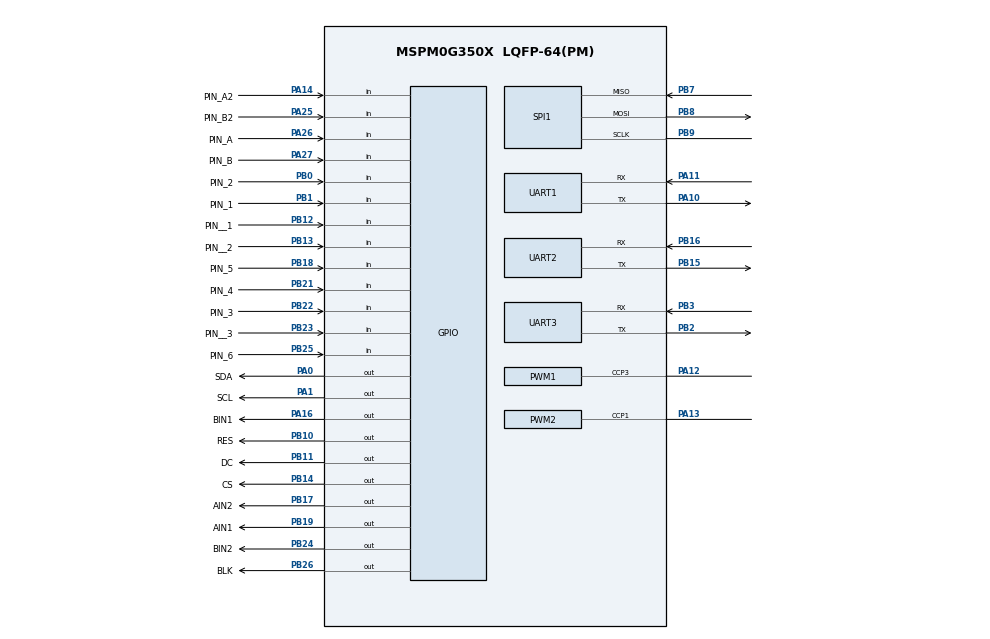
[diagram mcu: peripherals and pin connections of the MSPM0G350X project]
/**
 * @cliArgs --device "MSPM0G350X" --part "Default" --package "LQFP-64(PM)" --product "mspm0_sdk@2.11.00.07"
 * @versions {"tool":"1.26.2+4477"}
 */

/**
 * Import the modules used in this configuration.
 */
const GPIO    = scripting.addModule("/ti/driverlib/GPIO", {}, false);
const GPIO1   = GPIO.addInstance();
const GPIO2   = GPIO.addInstance();
const GPIO3   = GPIO.addInstance();
const GPIO4   = GPIO.addInstance();
const GPIO5   = GPIO.addInstance();
const GPIO6   = GPIO.addInstance();
const NONMAIN = scripting.addModule("/ti/driverlib/NONMAIN");
const PWM     = scripting.addModule("/ti/driverlib/PWM", {}, false);
const PWM1    = PWM.addInstance();
const PWM2    = PWM.addInstance();
const SPI     = scripting.addModule("/ti/driverlib/SPI", {}, false);
const SPI1    = SPI.addInstance();
const SYSCTL  = scripting.addModule("/ti/driverlib/SYSCTL");
const TIMER   = scripting.addModule("/ti/driverlib/TIMER", {}, false);
const TIMER1  = TIMER.addInstance();
const UART    = scripting.addModule("/ti/driverlib/UART", {}, false);
const UART1   = UART.addInstance();
const UART2   = UART.addInstance();
const UART3   = UART.addInstance();
const UART4   = UART.addInstance();

/**
 * Write custom configuration values to the imported modules.
 */
const gate7  = system.clockTree["MFCLKGATE"];
gate7.enable = true;

GPIO1.$name                          = "TB6612";
GPIO1.associatedPins.create(4);
GPIO1.associatedPins[0].$name        = "AIN1";
GPIO1.associatedPins[0].initialValue = "SET";
GPIO1.associatedPins[0].assignedPort = "PORTB";
GPIO1.associatedPins[0].assignedPin  = "19";
GPIO1.associatedPins[0].pin.$assign  = "PB19";
GPIO1.associatedPins[1].$name        = "AIN2";
GPIO1.associatedPins[1].initialValue = "SET";
GPIO1.associatedPins[1].assignedPort = "PORTB";
GPIO1.associatedPins[1].assignedPin  = "17";
GPIO1.associatedPins[1].pin.$assign  = "PB17";
GPIO1.associatedPins[2].$name        = "BIN1";
GPIO1.associatedPins[2].initialValue = "SET";
GPIO1.associatedPins[2].assignedPort = "PORTA";
GPIO1.associatedPins[2].assignedPin  = "16";
GPIO1.associatedPins[2].pin.$assign  = "PA16";
GPIO1.associatedPins[3].$name        = "BIN2";
GPIO1.associatedPins[3].initialValue = "SET";
GPIO1.associatedPins[3].assignedPort = "PORTB";
GPIO1.associatedPins[3].assignedPin  = "24";
GPIO1.associatedPins[3].pin.$assign  = "PB24";

const Board = scripting.addModule("/ti/driverlib/Board", {}, false);

GPIO2.$name                         = "LCD";
GPIO2.port                          = "PORTB";
GPIO2.associatedPins.create(4);
GPIO2.associatedPins[0].$name       = "RES";
GPIO2.associatedPins[0].ioStructure = "SD";
GPIO2.associatedPins[0].assignedPin = "10";
GPIO2.associatedPins[0].pin.$assign = "PB10";
GPIO2.associatedPins[1].$name       = "DC";
GPIO2.associatedPins[1].ioStructure = "SD";
GPIO2.associatedPins[1].assignedPin = "11";
GPIO2.associatedPins[1].pin.$assign = "PB11";
GPIO2.associatedPins[2].$name       = "CS";
GPIO2.associatedPins[2].assignedPin = "14";
GPIO2.associatedPins[2].ioStructure = "SD";
GPIO2.associatedPins[2].pin.$assign = "PB14";
GPIO2.associatedPins[3].$name       = "BLK";
GPIO2.associatedPins[3].ioStructure = "SD";
GPIO2.associatedPins[3].assignedPin = "26";
GPIO2.associatedPins[3].pin.$assign = "PB26";

GPIO3.port                                = "PORTA";
GPIO3.$name                               = "ENCODER";
GPIO3.associatedPins.create(4);
GPIO3.associatedPins[0].direction         = "INPUT";
GPIO3.associatedPins[0].interruptEn       = true;
GPIO3.associatedPins[0].interruptPriority = "0";
GPIO3.associatedPins[0].polarity          = "RISE";
GPIO3.associatedPins[0].$name             = "PIN_A";
GPIO3.associatedPins[0].assignedPin       = "26";
GPIO3.associatedPins[0].pin.$assign       = "PA26";
GPIO3.associatedPins[1].direction         = "INPUT";
GPIO3.associatedPins[1].interruptEn       = true;
GPIO3.associatedPins[1].polarity          = "RISE";
GPIO3.associatedPins[1].$name             = "PIN_B";
GPIO3.associatedPins[1].interruptPriority = "3";
GPIO3.associatedPins[1].assignedPin       = "27";
GPIO3.associatedPins[1].pin.$assign       = "PA27";
GPIO3.associatedPins[2].$name             = "PIN_A2";
GPIO3.associatedPins[2].direction         = "INPUT";
GPIO3.associatedPins[2].interruptEn       = true;
GPIO3.associatedPins[2].interruptPriority = "0";
GPIO3.associatedPins[2].polarity          = "RISE";
GPIO3.associatedPins[2].assignedPin       = "14";
GPIO3.associatedPins[2].pin.$assign       = "PA14";
GPIO3.associatedPins[3].$name             = "PIN_B2";
GPIO3.associatedPins[3].direction         = "INPUT";
GPIO3.associatedPins[3].interruptEn       = true;
GPIO3.associatedPins[3].polarity          = "RISE";
GPIO3.associatedPins[3].assignedPin       = "25";
GPIO3.associatedPins[3].pin.$assign       = "PA25";

GPIO4.$name                              = "TRACKING";
GPIO4.port                               = "PORTB";
GPIO4.associatedPins.create(6);
GPIO4.associatedPins[0].$name            = "PIN_1";
GPIO4.associatedPins[0].direction        = "INPUT";
GPIO4.associatedPins[0].internalResistor = "PULL_UP";
GPIO4.associatedPins[0].assignedPin      = "1";
GPIO4.associatedPins[0].pin.$assign      = "PB1";
GPIO4.associatedPins[1].$name            = "PIN_2";
GPIO4.associatedPins[1].direction        = "INPUT";
GPIO4.associatedPins[1].internalResistor = "PULL_UP";
GPIO4.associatedPins[1].assignedPin      = "0";
GPIO4.associatedPins[1].pin.$assign      = "PB0";
GPIO4.associatedPins[2].$name            = "PIN_3";
GPIO4.associatedPins[2].direction        = "INPUT";
GPIO4.associatedPins[2].internalResistor = "PULL_UP";
GPIO4.associatedPins[2].assignedPin      = "22";
GPIO4.associatedPins[2].pin.$assign      = "PB22";
GPIO4.associatedPins[3].$name            = "PIN_4";
GPIO4.associatedPins[3].direction        = "INPUT";
GPIO4.associatedPins[3].internalResistor = "PULL_UP";
GPIO4.associatedPins[3].assignedPin      = "21";
GPIO4.associatedPins[3].pin.$assign      = "PB21";
GPIO4.associatedPins[4].$name            = "PIN_5";
GPIO4.associatedPins[4].direction        = "INPUT";
GPIO4.associatedPins[4].internalResistor = "PULL_UP";
GPIO4.associatedPins[4].assignedPin      = "18";
GPIO4.associatedPins[4].pin.$assign      = "PB18";
GPIO4.associatedPins[5].$name            = "PIN_6";
GPIO4.associatedPins[5].direction        = "INPUT";
GPIO4.associatedPins[5].internalResistor = "PULL_UP";
GPIO4.associatedPins[5].assignedPin      = "25";
GPIO4.associatedPins[5].pin.$assign      = "PB25";

GPIO5.$name                          = "IIC_Software";
GPIO5.port                           = "PORTA";
GPIO5.associatedPins.create(2);
GPIO5.associatedPins[0].$name        = "SCL";
GPIO5.associatedPins[0].assignedPin  = "1";
GPIO5.associatedPins[0].initialValue = "SET";
GPIO5.associatedPins[0].ioStructure  = "OD";
GPIO5.associatedPins[0].pin.$assign  = "PA1";
GPIO5.associatedPins[1].$name        = "SDA";
GPIO5.associatedPins[1].ioStructure  = "OD";
GPIO5.associatedPins[1].initialValue = "SET";
GPIO5.associatedPins[1].assignedPin  = "0";
GPIO5.associatedPins[1].pin.$assign  = "PA0";

GPIO6.port                               = "PORTB";
GPIO6.$name                              = "KEY";
GPIO6.associatedPins.create(3);
GPIO6.associatedPins[0].direction        = "INPUT";
GPIO6.associatedPins[0].internalResistor = "PULL_UP";
GPIO6.associatedPins[0].$name            = "PIN__1";
GPIO6.associatedPins[0].assignedPin      = "12";
GPIO6.associatedPins[0].pin.$assign      = "PB12";
GPIO6.associatedPins[1].direction        = "INPUT";
GPIO6.associatedPins[1].internalResistor = "PULL_UP";
GPIO6.associatedPins[1].$name            = "PIN__2";
GPIO6.associatedPins[1].assignedPin      = "13";
GPIO6.associatedPins[1].pin.$assign      = "PB13";
GPIO6.associatedPins[2].$name            = "PIN__3";
GPIO6.associatedPins[2].direction        = "INPUT";
GPIO6.associatedPins[2].internalResistor = "PULL_UP";
GPIO6.associatedPins[2].assignedPin      = "23";
GPIO6.associatedPins[2].pin.$assign      = "PB23";

NONMAIN.nonmainWarning = true;
NONMAIN.bslMode        = false;

PWM1.$name                      = "PWM_0";
PWM1.timerStartTimer            = true;
PWM1.clockDivider               = 8;
PWM1.ccIndex                    = [3];
PWM1.peripheral.$assign         = "TIMA0";
PWM1.peripheral.ccp3Pin.$assign = "PA12";
PWM1.PWM_CHANNEL_3.$name        = "ti_driverlib_pwm_PWMTimerCC0";
PWM1.PWM_CHANNEL_3.invert       = true;
PWM1.ccp3PinConfig.$name        = "ti_driverlib_gpio_GPIOPinGeneric0";

PWM2.$name                      = "PWM_1";
PWM2.clockDivider               = 8;
PWM2.timerStartTimer            = true;
PWM2.ccIndex                    = [1];
PWM2.ccp1PinConfig.$name        = "ti_driverlib_gpio_GPIOPinGeneric1";
PWM2.peripheral.$assign         = "TIMG0";
PWM2.peripheral.ccp1Pin.$assign = "PA13";
PWM2.PWM_CHANNEL_1.$name        = "ti_driverlib_pwm_PWMTimerCC1";
PWM2.PWM_CHANNEL_1.invert       = true;

SPI1.$name                              = "SPI_LCD";
SPI1.targetBitRate                      = 2000000;
SPI1.frameFormat                        = "MOTO3";
SPI1.sclkPinConfig.direction            = scripting.forceWrite("OUTPUT");
SPI1.sclkPinConfig.onlyInternalResistor = scripting.forceWrite(false);
SPI1.sclkPinConfig.passedPeripheralType = scripting.forceWrite("Digital");
SPI1.sclkPinConfig.$name                = "ti_driverlib_gpio_GPIOPinGeneric2";
SPI1.mosiPinConfig.direction            = scripting.forceWrite("OUTPUT");
SPI1.mosiPinConfig.hideOutputInversion  = scripting.forceWrite(false);
SPI1.mosiPinConfig.onlyInternalResistor = scripting.forceWrite(false);
SPI1.mosiPinConfig.passedPeripheralType = scripting.forceWrite("Digital");
SPI1.mosiPinConfig.$name                = "ti_driverlib_gpio_GPIOPinGeneric3";
SPI1.misoPinConfig.onlyInternalResistor = scripting.forceWrite(false);
SPI1.misoPinConfig.passedPeripheralType = scripting.forceWrite("Digital");
SPI1.misoPinConfig.$name                = "ti_driverlib_gpio_GPIOPinGeneric4";
SPI1.peripheral.$assign                 = "SPI1";
SPI1.peripheral.sclkPin.$assign         = "PB9";
SPI1.peripheral.mosiPin.$assign         = "PB8";
SPI1.peripheral.misoPin.$assign         = "PB7";

SYSCTL.forceDefaultClkConfig = true;
SYSCTL.clockTreeEn           = true;

TIMER1.timerMode          = "PERIODIC";
TIMER1.interrupts         = ["ZERO"];
TIMER1.timerClkDiv        = 8;
TIMER1.timerStartTimer    = true;
TIMER1.$name              = "TIMER_TICK";
TIMER1.interruptPriority  = "3";
TIMER1.timerClkPrescale   = 100;
TIMER1.timerPeriod        = "1ms";
TIMER1.peripheral.$assign = "TIMA1";

UART1.$name                    = "UART_0";
UART1.uartClkSrc               = "MFCLK";
UART1.enabledInterrupts        = ["RX"];
UART1.targetBaudRate           = 115200;
UART1.peripheral.$assign       = "UART0";
UART1.peripheral.rxPin.$assign = "PA11";
UART1.peripheral.txPin.$assign = "PA10";
UART1.txPinConfig.$name        = "ti_driverlib_gpio_GPIOPinGeneric5";
UART1.rxPinConfig.$name        = "ti_driverlib_gpio_GPIOPinGeneric6";

UART2.uartClkSrc                       = "MFCLK";
UART2.targetBaudRate                   = 115200;
UART2.enabledInterrupts                = ["RX"];
UART2.$name                            = "UART_2";
UART2.peripheral.$assign               = "UART2";
UART2.peripheral.rxPin.$assign         = "PB16";
UART2.peripheral.txPin.$assign         = "PB15";
UART2.txPinConfig.direction            = scripting.forceWrite("OUTPUT");
UART2.txPinConfig.hideOutputInversion  = scripting.forceWrite(false);
UART2.txPinConfig.onlyInternalResistor = scripting.forceWrite(false);
UART2.txPinConfig.passedPeripheralType = scripting.forceWrite("Digital");
UART2.txPinConfig.$name                = "ti_driverlib_gpio_GPIOPinGeneric7";
UART2.rxPinConfig.hideOutputInversion  = scripting.forceWrite(false);
UART2.rxPinConfig.onlyInternalResistor = scripting.forceWrite(false);
UART2.rxPinConfig.passedPeripheralType = scripting.forceWrite("Digital");
UART2.rxPinConfig.$name                = "ti_driverlib_gpio_GPIOPinGeneric8";

UART3.uartClkSrc                       = "MFCLK";
UART3.targetBaudRate                   = 115200;
UART3.enabledInterrupts                = ["RX"];
UART3.$name                            = "UART_3";
UART3.peripheral.$assign               = "UART3";
UART3.peripheral.rxPin.$assign         = "PB3";
UART3.peripheral.txPin.$assign         = "PB2";
UART3.txPinConfig.direction            = scripting.forceWrite("OUTPUT");
UART3.txPinConfig.hideOutputInversion  = scripting.forceWrite(false);
UART3.txPinConfig.onlyInternalResistor = scripting.forceWrite(false);
UART3.txPinConfig.passedPeripheralType = scripting.forceWrite("Digital");
UART3.txPinConfig.$name                = "ti_driverlib_gpio_GPIOPinGeneric9";
UART3.rxPinConfig.hideOutputInversion  = scripting.forceWrite(false);
UART3.rxPinConfig.onlyInternalResistor = scripting.forceWrite(false);
UART3.rxPinConfig.passedPeripheralType = scripting.forceWrite("Digital");
UART3.rxPinConfig.$name                = "ti_driverlib_gpio_GPIOPinGeneric10";

UART4.$name                            = "UART_1";
UART4.uartClkSrc                       = "MFCLK";
UART4.targetBaudRate                   = 115200;
UART4.enabledInterrupts                = ["RX"];
UART4.txPinConfig.direction            = scripting.forceWrite("OUTPUT");
UART4.txPinConfig.hideOutputInversion  = scripting.forceWrite(false);
UART4.txPinConfig.onlyInternalResistor = scripting.forceWrite(false);
UART4.txPinConfig.passedPeripheralType = scripting.forceWrite("Digital");
UART4.txPinConfig.$name                = "ti_driverlib_gpio_GPIOPinGeneric11";
UART4.rxPinConfig.hideOutputInversion  = scripting.forceWrite(false);
UART4.rxPinConfig.onlyInternalResistor = scripting.forceWrite(false);
UART4.rxPinConfig.passedPeripheralType = scripting.forceWrite("Digital");
UART4.rxPinConfig.$name                = "ti_driverlib_gpio_GPIOPinGeneric12";

/**
 * Pinmux solution for unlocked pins/peripherals. This ensures that minor changes to the automatic solver in a future
 * version of the tool will not impact the pinmux you originally saw.  These lines can be completely deleted in order to
 * re-solve from scratch.
 */
Board.peripheral.$suggestSolution          = "DEBUGSS";
Board.peripheral.swclkPin.$suggestSolution = "PA20";
Board.peripheral.swdioPin.$suggestSolution = "PA19";
UART4.peripheral.$suggestSolution          = "UART1";
UART4.peripheral.rxPin.$suggestSolution    = "PA18";
UART4.peripheral.txPin.$suggestSolution    = "PA17";
